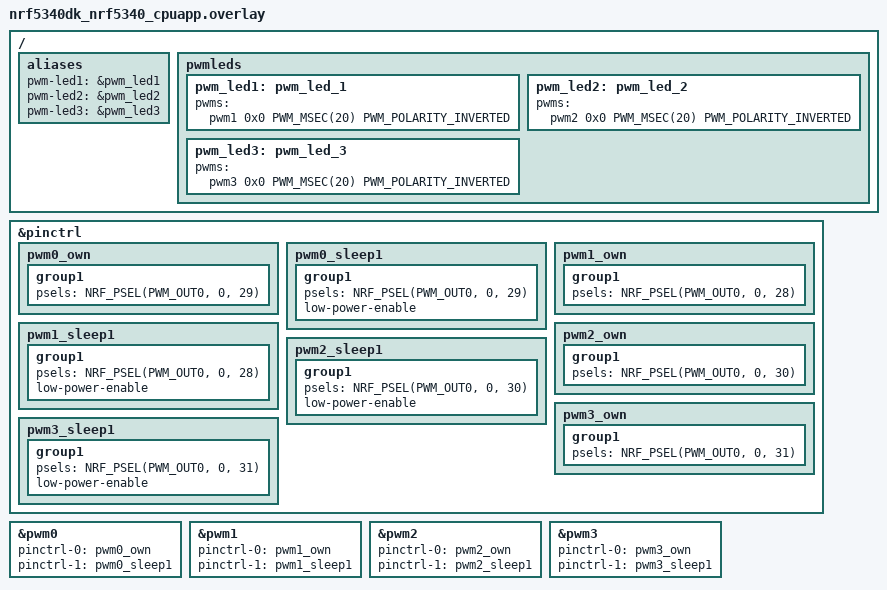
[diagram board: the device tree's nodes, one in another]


&pinctrl {
    pwm0_own: pwm0_own {
        group1 {
		    psels = <NRF_PSEL(PWM_OUT0, 0, 29)>;
	    };
    };

    pwm0_sleep1: pwm0_sleep1 {
	    group1 {
		    psels = <NRF_PSEL(PWM_OUT0, 0, 29)>;
		    low-power-enable;
	    };
    };

    pwm1_own: pwm1_own {
        group1 {
		    psels = <NRF_PSEL(PWM_OUT0, 0, 28)>;
	    };
    };

    pwm1_sleep1: pwm1_sleep1 {
	    group1 {
		    psels = <NRF_PSEL(PWM_OUT0, 0, 28)>;
		    low-power-enable;
	    };
    };


    pwm2_own: pwm2_own {
        group1 {
		    psels = <NRF_PSEL(PWM_OUT0, 0, 30)>;
	    };
    };

    pwm2_sleep1: pwm2_sleep1 {
	    group1 {
		    psels = <NRF_PSEL(PWM_OUT0, 0, 30)>;
		    low-power-enable;
	    };
    };

    pwm3_own: pwm3_own {
        group1 {
		    psels = <NRF_PSEL(PWM_OUT0, 0, 31)>;
	    };
    };

    pwm3_sleep1: pwm3_sleep1 {
	    group1 {
		    psels = <NRF_PSEL(PWM_OUT0, 0, 31)>;
		    low-power-enable;
	    };
    };
};

/ {
    aliases {
		pwm-led1 = &pwm_led1;
        pwm-led2 = &pwm_led2;
        pwm-led3 = &pwm_led3;
	};
    pwmleds {

        pwm_led1: pwm_led_1 {
			pwms = < &pwm1 0x0 PWM_MSEC(20) PWM_POLARITY_INVERTED >; /* in zephyr/boards/nordic/nrf5340dk/nrf5340_cpuapp_common.dtsi:27 */
		};

        pwm_led2: pwm_led_2 {
			pwms = < &pwm2 0x0 PWM_MSEC(20) PWM_POLARITY_INVERTED >; /* in zephyr/boards/nordic/nrf5340dk/nrf5340_cpuapp_common.dtsi:27 */
		};

        pwm_led3: pwm_led_3 {
			pwms = < &pwm3 0x0 PWM_MSEC(20) PWM_POLARITY_INVERTED >; /* in zephyr/boards/nordic/nrf5340dk/nrf5340_cpuapp_common.dtsi:27 */
		};

    };
};



// &pwm0_default {
//         group1 {
// 		    psels = <NRF_PSEL(PWM_OUT0, 0, 29)>;
// 	    };
//     };

//     &pwm0_sleep {
// 	    group1 {
// 		    psels = <NRF_PSEL(PWM_OUT0, 0, 29)>;
// 		    low-power-enable;
// 	    };
//     };


&pwm0 {
    pinctrl-0 = < &pwm0_own >;
	pinctrl-1 = < &pwm0_sleep1 >;
};

&pwm1 {
    status = "okay";
    pinctrl-0 = < &pwm1_own >;
	pinctrl-1 = < &pwm1_sleep1 >;
    pinctrl-names = "default",
				    "sleep";
};

&pwm2 {
    status = "okay";
    pinctrl-0 = < &pwm2_own >;
	pinctrl-1 = < &pwm2_sleep1 >;
    pinctrl-names = "default",
				    "sleep";
};

&pwm3 {
    status = "okay";
    pinctrl-0 = < &pwm3_own >;
	pinctrl-1 = < &pwm3_sleep1 >;
    pinctrl-names = "default",
				    "sleep";
};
